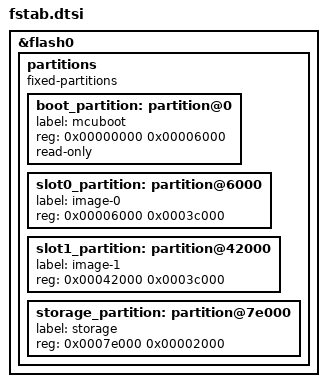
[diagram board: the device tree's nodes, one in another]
/*
 * Copyright (c) 2025 Arne Wendt (@bitmeal)
 * SPDX-License-Identifier: MPL-2.0
 */


/* Flash partition table for use with MCUBoot */
// &flash0 {
// 	partitions {
// 		compatible = "fixed-partitions";
// 		#address-cells = <1>;
// 		#size-cells = <1>;

// 		boot_partition: partition@0 {
// 			label = "mcuboot";
// 			reg = <0x00000000 0x6000>;
// 		};
// 		slot0_partition: partition@6000 {
// 			label = "image-0";
// 			reg = <0x00006000 0x3D000>;
// 		};
// 		slot1_partition: partition@43000 {
// 			label = "image-1";
// 			reg = <0x00043000 0x3D000>;
// 		};
// 	};
// };

&flash0 {
    partitions {
        compatible = "fixed-partitions";
        #address-cells = <1>;
        #size-cells = <1>;

        boot_partition: partition@0 {
            label = "mcuboot";
            reg = <0x00000000 0x00006000>;
            read-only;
        };

        slot0_partition: partition@6000 {
            label = "image-0";
            reg = <0x00006000 0x0003c000>;
        };
		
        slot1_partition: partition@42000 {
            label = "image-1";
            reg = <0x00042000 0x0003c000>;
        };

        storage_partition: partition@7e000 {
            label = "storage";
            reg = <0x0007e000 0x00002000>;
        };
    };
};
